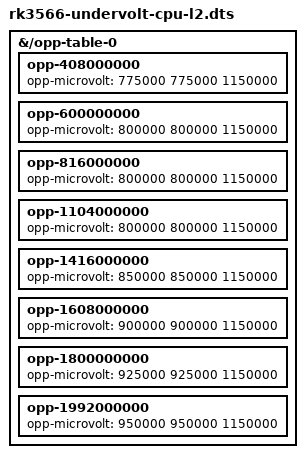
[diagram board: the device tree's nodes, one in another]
/dts-v1/;
/plugin/;

/ {
fragment@0 {
//target = <&cpu0_opp_table>;
        target-path = "/opp-table-0";
__overlay__ {
opp-408000000 {
opp-microvolt = <775000 775000 1150000>;
};
opp-600000000 {
opp-microvolt = <800000 800000 1150000>;
};
opp-816000000 {
opp-microvolt = <800000 800000 1150000>;
};
opp-1104000000 {
opp-microvolt = <800000 800000 1150000>;
};
opp-1416000000 {
opp-microvolt = <850000 850000 1150000>;
};
opp-1608000000 {
opp-microvolt = <900000 900000 1150000>;
};
opp-1800000000 {
opp-microvolt = <925000 925000 1150000>;
};
opp-1992000000 {
opp-microvolt = <950000 950000 1150000>;
};
};
};
};
